# CY8C5888LTI_LP097 register map
File version: 0.1
CY8C58LP
Registers are 32-bit, read-write, no defined reset value unless marked. A register's access mark holds for its fields unless they carry their own. Offsets are from the block's base; lines under a group give offsets from that group; [hi:lo] are bit positions; {n}, {i} and the like mark numbered series; 'fields as' and 'values as' point back to an identical list; <NAME> marks a mode.

## Memory map
0x00000000 ProtocovUSB — USBFS
0x00000000 Counter_1
0x00000000 VehicleBattVoltageAdc — SAR ADC
0x00000000 BluetoothUART — UART
0x00000000 VehicleCAN

## Counter_1
Base 0x00000000
0x40006406 Counter_1_COUNTER 16-bit — UDB.A0 - Current Counter Value
0x40006426 Counter_1_PERIOD 16-bit — UDB.D0 - Assigned Period
0x40006436 Counter_1_COMPARE 16-bit — UDB.D1 - Assigned Compare Value
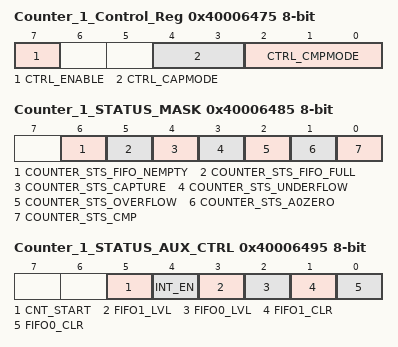
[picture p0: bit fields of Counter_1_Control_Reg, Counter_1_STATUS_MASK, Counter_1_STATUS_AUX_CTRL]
0x40006475 Counter_1_Control_Reg 8-bit — UDB Control Register - Assigned Control Register Value
  [7] CTRL_ENABLE — Enable Counter
  [4:3] CTRL_CAPMODE — Capture mode
  [2:0] CTRL_CMPMODE — Compare mode
0x40006485 Counter_1_STATUS_MASK 8-bit — UDB Status bits Interrupt Mask Enable Register
  [6] COUNTER_STS_FIFO_NEMPTY — FIFO Not Empty Status
  [5] COUNTER_STS_FIFO_FULL — FIFO Full Status
  [4] COUNTER_STS_CAPTURE — Capture Status
  [3] COUNTER_STS_UNDERFLOW — Underflow status
  [2] COUNTER_STS_OVERFLOW — Overflow status
  [1] COUNTER_STS_A0ZERO — A0 Zero ouput status
  [0] COUNTER_STS_CMP — Compare output status
0x40006495 Counter_1_STATUS_AUX_CTRL 8-bit — UDB Auxilliary Control Register
  [5] CNT_START — FIFO0 clear
    0=E_CNT_START0 (Disable counter); 1=E_CNT_START1 (Enable counter)
  [4] INT_EN
    0=E_INT_EN0 (Interrupt disabled); 1=E_INT_EN1 (Interrupt enabled)
  [3] FIFO1_LVL — FIFO level
    0=E_FIFO_LVL_0 (FIFO LVL: input mode: FIFO not full; output mode: FIFO not empty); 1=E_FIFO_LVL_1 (FIFO LVL: input mode: FIFO at least 1/2 empty; output mode: FIFO at least 1/2 full)
  [2] FIFO0_LVL — FIFO level
    values as FIFO1_LVL
  [1] FIFO1_CLR — FIFO1 clear
    0=E_FIFO_CLR_0 (Normal FIFO operation); 1=E_FIFO_CLR_1 (Clear FIFO state)
  [0] FIFO0_CLR — FIFO0 clear
    values as FIFO1_CLR

## VehicleBattVoltageAdc — SAR ADC
Base 0x00000000
0x40004616 SAR_TR0 8-bit — SAR trim register
{0x40005908+i} SAR_CSR{i} 8-bit (i=0..6) — SAR status and control register {i}
0x40005B28 SAR_SW0 8-bit — SAR Analog Routing Register 0
{0x40005B28+i} SAR_SW{i} 8-bit (i=2..4) — SAR Analog Routing Register {i}
0x40005B2E SAR_SW6 8-bit — SAR Analog Routing Register 6
0x40005B2F SAR_CLK 8-bit — SAR Clock Selection Register
0x40005BA2 SAR_WRK 16-bit — SAR working register

## BluetoothUART — UART
Base 0x00000000
0x40006423 RX_BluetoothUART_RX_ADDRESS1 8-bit — RX Address1 Register
0x40006433 RX_BluetoothUART_RX_ADDRESS2 8-bit — RX Address2 Register
0x40006442 TX_BluetoothUART_TX_DATA 8-bit — TX Data Register
0x40006443 RX_BluetoothUART_RX_DATA 8-bit — RX Data Register
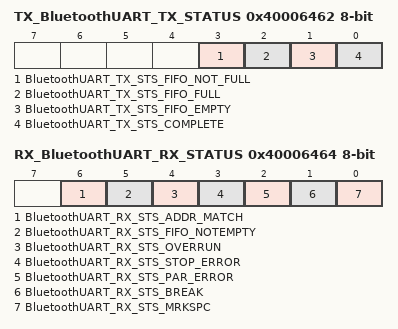
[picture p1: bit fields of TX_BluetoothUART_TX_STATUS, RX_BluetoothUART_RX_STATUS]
0x40006462 TX_BluetoothUART_TX_STATUS 8-bit — TX status register
  [3] BluetoothUART_TX_STS_FIFO_NOT_FULL ro, [2] BluetoothUART_TX_STS_FIFO_FULL ro, [1] BluetoothUART_TX_STS_FIFO_EMPTY ro, [0] BluetoothUART_TX_STS_COMPLETE ro
0x40006464 RX_BluetoothUART_RX_STATUS 8-bit — RX status register
  [6] BluetoothUART_RX_STS_ADDR_MATCH ro, [5] BluetoothUART_RX_STS_FIFO_NOTEMPTY ro, [4] BluetoothUART_RX_STS_OVERRUN ro, [3] BluetoothUART_RX_STS_STOP_ERROR ro, [2] BluetoothUART_RX_STS_PAR_ERROR ro, [1] BluetoothUART_RX_STS_BREAK ro, [0] BluetoothUART_RX_STS_MRKSPC ro

## VehicleCAN
Base 0x00000000
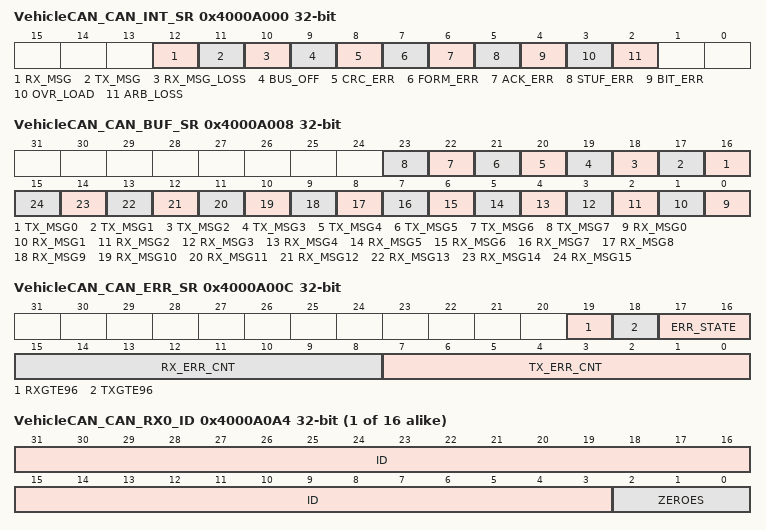
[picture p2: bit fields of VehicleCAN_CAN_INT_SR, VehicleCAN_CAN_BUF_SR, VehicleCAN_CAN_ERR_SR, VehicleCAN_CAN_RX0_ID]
0x4000A000 VehicleCAN_CAN_INT_SR — The interrupt status register stores internal interrupt events. ? Once a bit is set it remains set until it is cleared by writing a '1' to it. ? The interrupt enable register has no effect on the interrupt status register. ? A pending interrupt occurs when the flag is set to '1'. To acknowledge an interrupt, set the flag to '1'
  [12] RX_MSG — Msg Recieved
  [11] TX_MSG — Tx msg Sent
  [10] RX_MSG_LOSS — Rx msg loss Interrupt
  [9] BUS_OFF — Bus Off State
  [8] CRC_ERR — CRC Error Interrupt
  [7] FORM_ERR — Form Error Interrupt
  [6] ACK_ERR — Ack Error Interrupt
  [5] STUF_ERR — Stuff Error Interrupt
  [4] BIT_ERR — Bit Error Interrupt
  [3] OVR_LOAD — Overload Interrupt
  [2] ARB_LOSS — Arbitration Loss
0x4000A008 VehicleCAN_CAN_BUF_SR — These status indicators bundle the respective flags from all RxMessage and TxMessage buffers. ? Note All flags are read only. To acknowledge a MsgAv flag, the CPU must write to the respective RxMessage buffer
  [n+16] TX_MSG{n} (n=0..7) — Tx req Pending for Tx Msg{n}
  [n] RX_MSG{n} (n=0..15) — Rx Msg{n} Available
0x4000A00C VehicleCAN_CAN_ERR_SR — Status indicators are provided to report the CAN controller error state, receive error count, and transmit error count. ? Special flags report error counter values equal to or in excess of 96 errors are available to indicate heavily disturbed bus situations. ? The transmitter error counter according to the CAN standard. When it is greater than 255 Decimal, it is fixed at 255 Decimal.
  [19] RXGTE96 — Rx Error Count is greater or equal to 96 Decimal
  [18] TXGTE96 — Tx Error Count is greater or equal to 96 Decimal
  [17:16] ERR_STATE — Error State of CAN node, 00 error active, 01 error passive, 1x bus off
  [15:8] RX_ERR_CNT — Rx error Count. When in bus-off state,this counter is used to count 128 groups of 11 recessive bits
  [7:0] TX_ERR_CNT — Tx error Count
{0x4000A024+0x10*i} VehicleCAN_CAN_TX{i}_ID (i=0..7) — CAN Tx Msg Identifier
  [31:3] ID — Tx Msg Indentifier
{0x4000A028+0x10*i} VehicleCAN_CAN_TX{i}_DH (i=0..7) — CAN Tx Msg Upper Data Bytes
  [31:0] DATA_HIGH — Upper Data Bytes
{0x4000A02C+0x10*i} VehicleCAN_CAN_TX{i}_DL (i=0..7) — CAN Tx Msg Lower Data Bytes
  [31:0] DATA_LOW — Lower Data Bytes
{0x4000A0A4+0x20*i} VehicleCAN_CAN_RX{i}_ID (i=0..15) — The register contains Rx Msg Identifier
  [31:3] ID — Rx Msg Indentifier
  [2:0] ZEROES — zeros
{0x4000A0A8+0x20*i} VehicleCAN_CAN_RX{i}_DH (i=0..15) — The register contains the Rx Msg Upper Data Bytes
  [31:0] DATA_HIGH — Upper Data Bytes
{0x4000A0AC+0x20*i} VehicleCAN_CAN_RX{i}_DL (i=0..15) — The register contains the Rx Msg Lover Data Bytes
  [31:0] DATA_LOW — Lower Data Bytes
